# ADuCM350 register map
Vendor: Analog Devices; Series: ARMCM3; File version: 0.1
CPU: CM3 r2p1, little endian, no MPU, no FPU, 3 interrupt priority bits
Registers are 16-bit, access not given, no defined reset value unless marked. A register's access mark holds for its fields unless they carry their own. Offsets are from the block's base; [hi:lo] are bit positions.

## I2C — I2C Master/Slave
Base 0x40003000
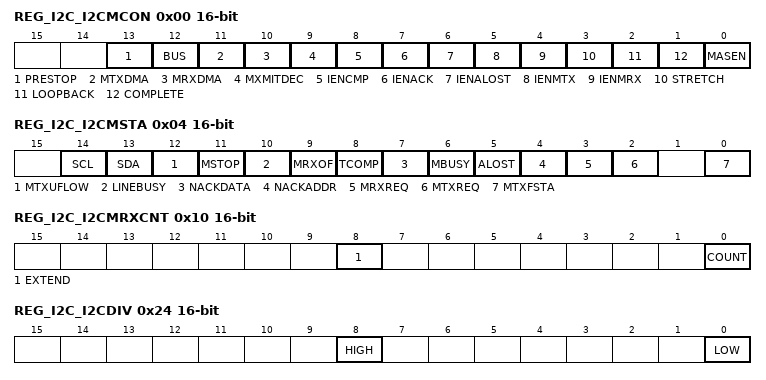
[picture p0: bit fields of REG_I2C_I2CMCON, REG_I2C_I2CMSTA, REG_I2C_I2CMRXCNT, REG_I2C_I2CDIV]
0x00 REG_I2C_I2CMCON — I2C Master control
  [13] PRESTOP — Prestop Bus-Clear
  [12] BUS — Bus-Clear Enable
  [11] MTXDMA — Enable master Tx DMA request
  [10] MRXDMA — Enable master Rx DMA request
  [9] MXMITDEC — Decrement master TX FIFO status when a byte has been transmitted
  [8] IENCMP — Transaction completed (or stop detected) interrupt enable
  [7] IENACK — ACK not received interrupt enable
  [6] IENALOST — Arbitration lost interrupt enable
  [5] IENMTX — Transmit request interrupt enable.
  [4] IENMRX — Receive request interrupt enable
  [3] STRETCH — Stretch SCL enable
  [2] LOOPBACK — Internal loopback enable
  [1] COMPLETE — Start back-off disable
  [0] MASEN — Master enable
0x04 REG_I2C_I2CMSTA — I2C Master status
  [14] SCL — State of SCL Line
  [13] SDA — State of SDA Line
  [12] MTXUFLOW — Master Transmit Underflow
  [11] MSTOP — STOP driven by this I2C Master
  [10] LINEBUSY — Line is busy
  [9] MRXOF — Master Receive FIFO overflow
  [8] TCOMP — Transaction complete or stop detected
  [7] NACKDATA — ACK not received in response to data write
  [6] MBUSY — Master busy
  [5] ALOST — Arbitration lost
  [4] NACKADDR — ACK not received in response to an address
  [3] MRXREQ — Master Receive request
  [2] MTXREQ — Master Transmit request
  [0] MTXFSTA — Master Transmit FIFO status
0x08 REG_I2C_I2CMRX — I2C Master receive data
  [0] I2CMRX — Master receive register
0x0C REG_I2C_I2CMTX — I2C Master transmit data
  [0] I2CMTX — Master transmit register
0x10 REG_I2C_I2CMRXCNT — I2C Master receive data count
  [8] EXTEND — Extended read
  [0] COUNT — Receive count
0x14 REG_I2C_I2CMCRXCNT — I2C Master current receive data count
  [0] COUNT — Current receive count
0x18 REG_I2C_I2CADR1 — I2C 1st master address byte
  [0] ADR1 — Address byte 1
0x1C REG_I2C_I2CADR2 — I2C 2nd master address byte
  [0] ADR2 — Address byte 2
0x20 REG_I2C_I2CBYT — I2C Start byte
  [0] SBYTE — Start byte
0x24 REG_I2C_I2CDIV — I2C Serial clock period divisor
  [8] HIGH — Serial clock high time
  [0] LOW — Serial clock low time
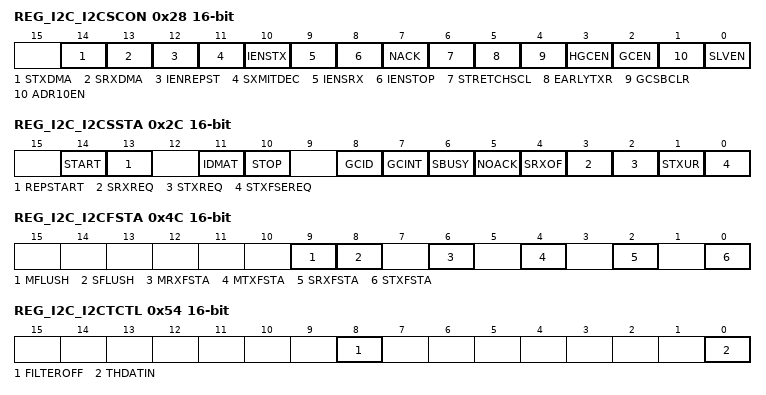
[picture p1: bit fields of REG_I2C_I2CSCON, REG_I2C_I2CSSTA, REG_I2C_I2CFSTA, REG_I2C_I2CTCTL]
0x28 REG_I2C_I2CSCON — I2C Slave control
  [14] STXDMA — Enable slave Tx DMA request
  [13] SRXDMA — Enable slave Rx DMA request
  [12] IENREPST — Repeated start interrupt enable
  [11] SXMITDEC — Decrement Slave Tx FIFO status when a byte has been transmitted
  [10] IENSTX — Slave Transmit request interrupt enable
  [9] IENSRX — Slave Receive request interrupt enable
  [8] IENSTOP — Stop condition detected interrupt enable
  [7] NACK — NACK next communication
  [6] STRETCHSCL — Stretch SCL enable
  [5] EARLYTXR — Early transmit request mode
  [4] GCSBCLR — General call status bit clear
  [3] HGCEN — Hardware general call enable
  [2] GCEN — General call enable
  [1] ADR10EN — Enabled 10-bit addressing
  [0] SLVEN — Slave enable
0x2C REG_I2C_I2CSSTA — I2C Slave I2C Status/Error/IRQ
  [14] START — Start and matching address
  [13] REPSTART — Repeated start and matching address
  [11] IDMAT — Device ID matched
  [10] STOP — Stop after start and matching address
  [8] GCID — General ID
  [7] GCINT — General call interrupt
  [6] SBUSY — Slave busy
  [5] NOACK — Ack not generated by the slave
  [4] SRXOF — Slave Receive FIFO overflow
  [3] SRXREQ — Slave Receive request
  [2] STXREQ — Slave Transmit request
  [1] STXUR — Slave Transmit FIFO underflow
  [0] STXFSEREQ — Slave Tx FIFO Status or early request
0x30 REG_I2C_I2CSRX — I2C Slave receive
  [0] I2CSRX — Slave receive register
0x34 REG_I2C_I2CSTX — I2C Slave transmit
  [0] I2CSTX — Slave transmit register
0x38 REG_I2C_I2CALT — I2C Hardware general call ID
  [0] ALT — Slave Alt
0x3C REG_I2C_I2CID0 — I2C 1st slave address device ID
  [0] ID0 — Slave device ID 0
0x40 REG_I2C_I2CID1 — I2C 2nd slave address device ID
  [0] ID1 — Slave device ID 1
0x44 REG_I2C_I2CID2 — I2C 3rd slave address device ID
  [0] ID2 — Slave device ID 2
0x48 REG_I2C_I2CID3 — I2C 4th slave address device ID
  [0] ID3 — Slave device ID 3
0x4C REG_I2C_I2CFSTA — I2C Master and slave FIFO status
  [9] MFLUSH — Flush the master transmit FIFO
  [8] SFLUSH — Flush the slave transmit FIFO
  [6] MRXFSTA — Master receive FIFO status
  [4] MTXFSTA — Master transmit FIFO status
  [2] SRXFSTA — Slave receive FIFO status
  [0] STXFSTA — Slave transmit FIFO status
0x50 REG_I2C_I2CSHCON — I2C Shared control
  [0] RESET — Reset START STOP detect circuit
0x54 REG_I2C_I2CTCTL — I2C Timing Control Register
  [8] FILTEROFF — Input Filter Control
  [0] THDATIN — Data In Hold Start
